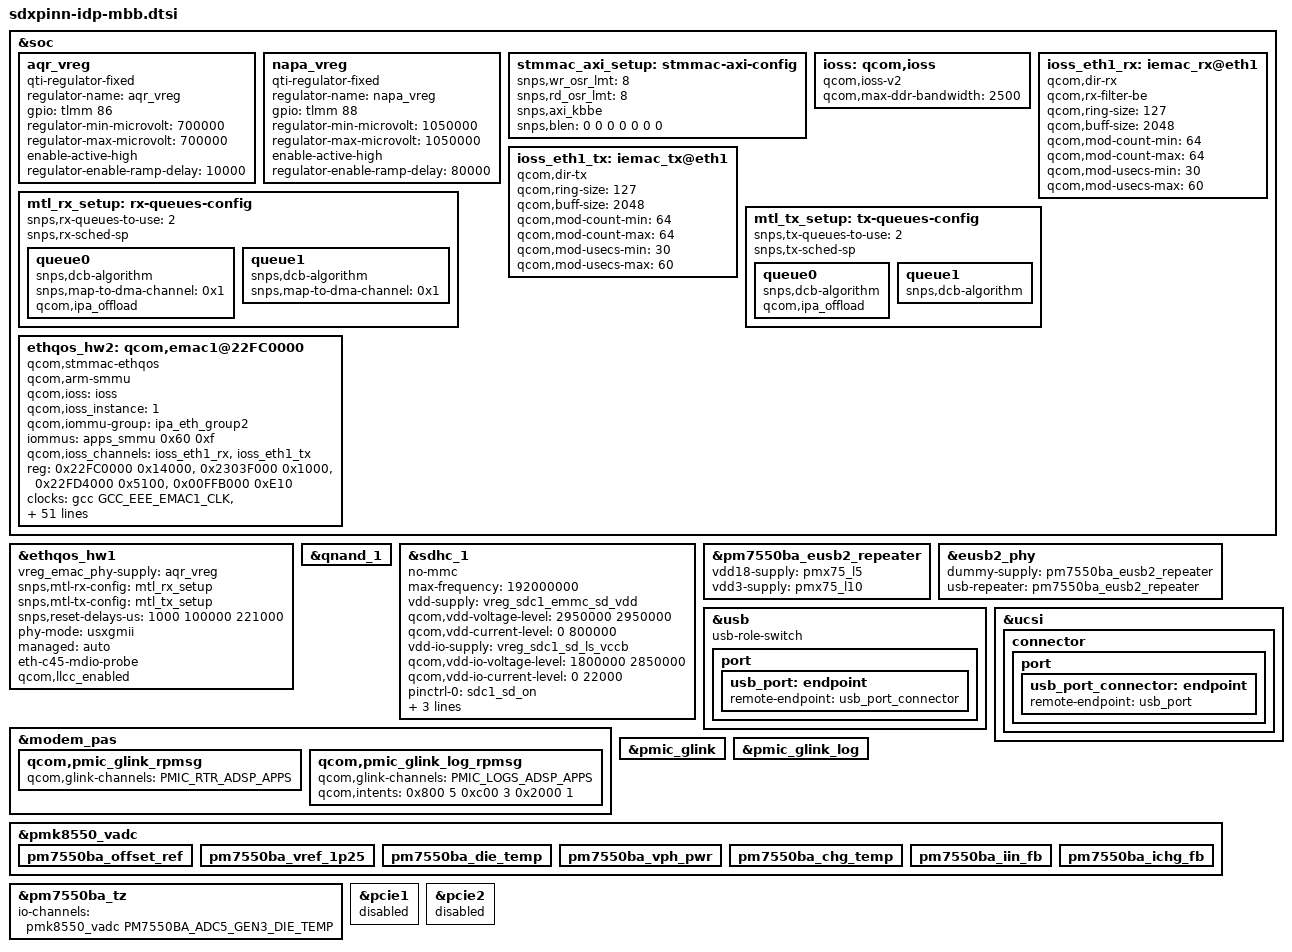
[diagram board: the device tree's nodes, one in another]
#include <dt-bindings/gpio/gpio.h>

#include "sdxpinn-pmic-overlay.dtsi"
#include "pm7550ba.dtsi"

&soc {
	aqr_vreg: aqr_vreg {
		compatible = "qti-regulator-fixed";
		regulator-name = "aqr_vreg";
		gpio = <&tlmm 86 GPIO_ACTIVE_HIGH>;
		regulator-min-microvolt = <700000>;
		regulator-max-microvolt = <700000>;
		enable-active-high;
		regulator-enable-ramp-delay = <10000>;
	};

	napa_vreg: napa_vreg {
		compatible = "qti-regulator-fixed";
		regulator-name = "napa_vreg";
		gpio = <&tlmm 88 GPIO_ACTIVE_HIGH>;
		regulator-min-microvolt = <1050000>;
		regulator-max-microvolt = <1050000>;
		enable-active-high;
		regulator-enable-ramp-delay = <80000>;
	};

	stmmac_axi_setup: stmmac-axi-config {
		snps,wr_osr_lmt = <8>;
		snps,rd_osr_lmt = <8>;
		snps,axi_kbbe;
		/* If FB is disabled, the AXI master chooses
		 * a burst length of any value less than the
		 * maximum enabled burst length
		 * (all lesser burst length enables are redundant).
		 */
		snps,blen = <0 0 0 0 0 0 0>;
	};

	ioss: qcom,ioss {
		compatible = "qcom,ioss-v2";
		qcom,max-ddr-bandwidth = <2500>;
	};

	ioss_eth1_rx: iemac_rx@eth1 {
		qcom,dir-rx;
		qcom,rx-filter-be;

		qcom,ring-size = <127>;
		qcom,buff-size = <2048>;

		qcom,mod-count-min = <64>;
		qcom,mod-count-max = <64>;
		qcom,mod-usecs-min = <30>;
		qcom,mod-usecs-max = <60>;
	};

	ioss_eth1_tx: iemac_tx@eth1 {
		qcom,dir-tx;
		qcom,ring-size = <127>;
		qcom,buff-size = <2048>;

		qcom,mod-count-min = <64>;
		qcom,mod-count-max = <64>;
		qcom,mod-usecs-min = <30>;
		qcom,mod-usecs-max = <60>;
	};

	mtl_rx_setup: rx-queues-config {
		snps,rx-queues-to-use = <2>;
		snps,rx-sched-sp;

		queue0 {
			snps,dcb-algorithm;
			snps,map-to-dma-channel = <0x1>;
			qcom,ipa_offload;
		};

		queue1 {
			snps,dcb-algorithm;
			snps,map-to-dma-channel = <0x1>;
		};
	};

	mtl_tx_setup: tx-queues-config {
		snps,tx-queues-to-use = <2>;
		snps,tx-sched-sp;
		queue0 {
			snps,dcb-algorithm;
			qcom,ipa_offload;
		};

		queue1 {
			snps,dcb-algorithm;
		};
	};

	ethqos_hw2: qcom,emac1@22FC0000 {
		compatible = "qcom,stmmac-ethqos", "snps,dwxgmac", "qcom,ioss-v2-device";
		qcom,arm-smmu;
		qcom,ioss = <&ioss>;
		qcom,ioss_instance = <1>;
		qcom,iommu-group = <&ipa_eth_group2>;
		iommus = <&apps_smmu 0x60 0xf>;

		qcom,ioss_channels =
			<&ioss_eth1_rx>,
			<&ioss_eth1_tx>;

		reg = <0x22FC0000 0x14000>,
			<0x2303F000 0x1000>,
			<0x22FD4000 0x5100>,
			<0x00FFB000 0xE10>;
		reg-names = "stmmaceth", "rgmii","xpcs","serdes";
		clocks = <&gcc GCC_EEE_EMAC1_CLK>,
			<&gcc GCC_EMAC1_AXI_CLK>,
			<&gcc GCC_EMAC1_CC_SGMIIPHY_RX_CLK>,
			<&gcc GCC_EMAC1_CC_SGMIIPHY_TX_CLK>,
			<&gcc GCC_EMAC1_PHY_AUX_CLK>,
			<&gcc GCC_EMAC1_PTP_CLK>,
			<&gcc GCC_EMAC1_RGMII_CLK>,
			<&gcc GCC_EMAC1_RPCS_RX_CLK>,
			<&gcc GCC_EMAC1_RPCS_TX_CLK>,
			<&gcc GCC_EMAC1_SLV_AHB_CLK>,
			<&gcc GCC_EMAC1_XGXS_RX_CLK>,
			<&gcc GCC_EMAC1_XGXS_TX_CLK>,
			<&gcc GCC_EMAC1_CC_SGMIIPHY_RX_CLK_SRC>,
			<&gcc GCC_EMAC1_CC_SGMIIPHY_TX_CLK_SRC>,
			<&gcc GCC_EMAC1_SGMIIPHY_MAC_RCLK_SRC>,
			<&gcc GCC_EMAC1_SGMIIPHY_MAC_TCLK_SRC>,
			<&emac1_sgmiiphy_rclk>,
			<&emac1_sgmiiphy_tclk>,
			<&emac1_sgmiiphy_mac_rclk>,
			<&emac1_sgmiiphy_mac_tclk>,
			<&gcc GCC_EMAC_1_CLKREF_EN>;
		clock-names = "eee", "stmmaceth", "sgmii_rx",
		"sgmii_tx", "phyaux", "ptp_ref", "rgmii",
		"pcs_rx", "pcs_tx", "pclk", "xgxs_rx",
		"xgxs_tx", "sgmii_rclk_src", "sgmii_tclk_src",
		"sgmii_mac_rclk_src", "sgmii_mac_tclk_src", "sgmii_rclk",
		"sgmii_tclk", "sgmii_mac_rclk", "sgmii_mac_tclk","sgmi_ref";

		interrupts-extended = <&intc GIC_SPI 445 IRQ_TYPE_LEVEL_HIGH>, <&intc GIC_SPI 76 IRQ_TYPE_LEVEL_HIGH>, <&tlmm 109 IRQ_TYPE_EDGE_FALLING>;

		interrupt-names = "macirq", "eth_lpi", "phy-intr";

		gdsc_emac-supply = <&gcc_emac1_gdsc>;
		pinctrl-names = "dev-emac1_mdc","dev-emac1_mdio","dev-emac1_pin_phy_intr",
		"dev-emac1_phy_reset_state";
		pinctrl-0 = <&emac1_mdc>;
		pinctrl-1 = <&emac1_mdio>;
		pinctrl-2 = <&emac1_pin_phy_intr>;
		pinctrl-3 = <&emac1_phy_reset_state>;

		vreg_a_sgmii_1p2-supply = <&L1B>;
		vreg_a_sgmii_0p9-supply = <&L4B>;
		vreg_emac_phy-supply = <&napa_vreg>;
		qcom,phy-intr-redirect = <&tlmm 109 IRQ_TYPE_EDGE_FALLING>;
		snps,reset= <&tlmm 108 1>;
		snps,crc_strip;

		interconnect-names = "axi_icc_path", "apb_icc_path";
		interconnects = <&system_noc MASTER_EMAC_1 &mc_virt SLAVE_EBI1>,
				<&gem_noc MASTER_APPSS_PROC &system_noc SLAVE_ETH1_CFG>;

		snps,tso;
		snps,pbl = <32>;
		rx-fifo-depth = <8192>;
		tx-fifo-depth = <8192>;
		snps,mtl-rx-config = <&mtl_rx_setup>;
		snps,mtl-tx-config = <&mtl_tx_setup>;

		snps,reset-active-low;
		snps,reset-delays-us = <0 11000 70000>;
		phy-mode = "sgmii";
		managed = "auto";
		eth-c22-mdio-probe;
		snps,axi-config = <&stmmac_axi_setup>;

	};
};

&ethqos_hw1 {
	vreg_emac_phy-supply = <&aqr_vreg>;
	snps,mtl-rx-config = <&mtl_rx_setup>;
	snps,mtl-tx-config = <&mtl_tx_setup>;

	snps,reset-delays-us = <1000 100000 221000>;
	phy-mode = "usxgmii";
	managed = "auto";
	eth-c45-mdio-probe;
	qcom,llcc_enabled;
};

&qnand_1 {
	status = "ok";
};

&sdhc_1 {
	status = "ok";

	no-mmc;
	max-frequency = <192000000>;

	vdd-supply = <&vreg_sdc1_emmc_sd_vdd>;
	qcom,vdd-voltage-level = <2950000 2950000>;
	qcom,vdd-current-level = <0 800000>;

	vdd-io-supply = <&vreg_sdc1_sd_ls_vccb>;
	qcom,vdd-io-voltage-level = <1800000 2850000>;
	qcom,vdd-io-current-level = <0 22000>;

	pinctrl-names = "default", "sleep";
	pinctrl-0 = <&sdc1_sd_on>;
	pinctrl-1 = <&sdc1_sd_off>;

	cd-gpios = <&tlmm 103 GPIO_ACTIVE_LOW>;

	operating-points-v2 = <&sdhc2_opp_table>;
};

&pm7550ba_eusb2_repeater {
	vdd18-supply = <&pmx75_l5>;
	vdd3-supply = <&pmx75_l10>;
	status = "ok";
};

&eusb2_phy {
	dummy-supply = <&pm7550ba_eusb2_repeater>;
	usb-repeater = <&pm7550ba_eusb2_repeater>;
};

&usb {
	usb-role-switch;
	port {
		usb_port: endpoint {
			remote-endpoint = <&usb_port_connector>;
		};
	};
};

&ucsi {
	connector {
		port {
			usb_port_connector: endpoint {
				remote-endpoint = <&usb_port>;
			};
		};
	};
};

&modem_pas {
	qcom,pmic_glink_rpmsg {
		qcom,glink-channels = "PMIC_RTR_ADSP_APPS";
	};

	qcom,pmic_glink_log_rpmsg {
		qcom,glink-channels = "PMIC_LOGS_ADSP_APPS";
		qcom,intents = <0x800 5
				0xc00 3
				0x2000 1>;
	};
};

&pmic_glink {
	status = "ok";
};

&pmic_glink_log {
	status = "ok";
};

&pmk8550_vadc {
	/* PM8550BA Channel nodes */
	pm7550ba_offset_ref {
		status = "ok";
	};

	pm7550ba_vref_1p25 {
		status = "ok";
	};

	pm7550ba_die_temp {
		status = "ok";
	};

	pm7550ba_vph_pwr {
		status = "ok";
	};

	pm7550ba_chg_temp {
		status = "ok";
	};

	pm7550ba_iin_fb {
		status = "ok";
	};

	pm7550ba_ichg_fb {
		status = "ok";
	};
};

&pm7550ba_tz {
	io-channels = <&pmk8550_vadc PM7550BA_ADC5_GEN3_DIE_TEMP>;
	io-channel-names = "thermal";
};

&pcie1 {
	status = "disabled";
};

&pcie2 {
	status = "disabled";
};
